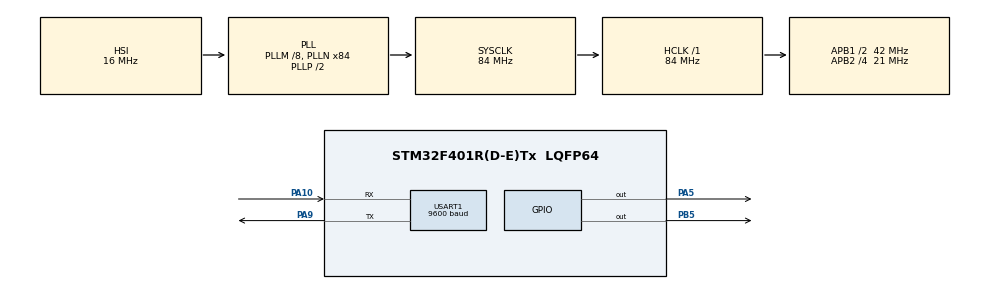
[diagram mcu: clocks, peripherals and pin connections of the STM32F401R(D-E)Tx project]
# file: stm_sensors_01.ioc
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Mcu.Family=STM32F4
Mcu.Name=STM32F401R(D-E)Tx
Mcu.Package=LQFP64
NVIC.PriorityGroup=NVIC_PRIORITYGROUP_4
NVIC.TIM1_BRK_TIM9_IRQn=true\:0\:0\:false\:false\:true\:true
NVIC.TIM1_UP_TIM10_IRQn=true\:0\:0\:false\:false\:true\:true
PA10.Mode=Asynchronous
PA10.Signal=USART1_RX
PA5.Signal=GPIO_Output
PA9.Mode=Asynchronous
PA9.Signal=USART1_TX
PB5.GPIO_ModeDefaultOutputPP=GPIO_MODE_OUTPUT_OD
PB5.GPIO_Speed=GPIO_SPEED_FREQ_VERY_HIGH
PB5.Signal=GPIO_Output
PH0\ -\ OSC_IN.Mode=HSE-External-Oscillator
PH0\ -\ OSC_IN.Signal=RCC_OSC_IN
PH1\ -\ OSC_OUT.Mode=HSE-External-Oscillator
PH1\ -\ OSC_OUT.Signal=RCC_OSC_OUT
ProjectManager.HeapSize=0x200
ProjectManager.StackSize=0x400
ProjectManager.TargetToolchain=SW4STM32
RCC.48MHZClocksFreq_Value=42000000
RCC.AHBFreq_Value=84000000
RCC.APB1CLKDivider=RCC_HCLK_DIV2
RCC.APB1Freq_Value=42000000
RCC.APB1TimFreq_Value=84000000
RCC.APB2CLKDivider=RCC_HCLK_DIV4
RCC.APB2Freq_Value=21000000
RCC.APB2TimFreq_Value=42000000
RCC.CortexFreq_Value=84000000
RCC.HCLKFreq_Value=84000000
RCC.HSE_VALUE=21000000
RCC.HSI_VALUE=16000000
RCC.LSE_VALUE=32768
RCC.PLLM=8
RCC.PLLN=84
RCC.SYSCLKFreq_VALUE=84000000
RCC.SYSCLKSource=RCC_SYSCLKSOURCE_PLLCLK
RCC.VCOOutputFreq_Value=168000000
TIM10.Period=49
TIM10.Prescaler=41999
TIM9.ClockDivision=TIM_CLOCKDIVISION_DIV1
TIM9.Period=999
TIM9.Prescaler=41999
USART1.BaudRate=9600
USART1.VirtualMode=VM_ASYNC
VP_TIM10_VS_ClockSourceINT.Mode=Enable_Timer
VP_TIM9_VS_ClockSourceINT.Mode=Internal
board=stm_sensors_01

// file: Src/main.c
/**
  ******************************************************************************
  * @file           : main.c
  * @brief          : Main program body
  ******************************************************************************
  ** This notice applies to any and all portions of this file
  * that are not between comment pairs USER CODE BEGIN and
  * USER CODE END. Other portions of this file, whether
  * inserted by the user or by software development tools
  * are owned by their respective copyright owners.
  *
  * COPYRIGHT(c) 2018 STMicroelectronics
  *
  * Redistribution and use in source and binary forms, with or without modification,
  * are permitted provided that the following conditions are met:
  *   1. Redistributions of source code must retain the above copyright notice,
  *      this list of conditions and the following disclaimer.
  *   2. Redistributions in binary form must reproduce the above copyright notice,
  *      this list of conditions and the following disclaimer in the documentation
  *      and/or other materials provided with the distribution.
  *   3. Neither the name of STMicroelectronics nor the names of its contributors
  *      may be used to endorse or promote products derived from this software
  *      without specific prior written permission.
  *
  * THIS SOFTWARE IS PROVIDED BY THE COPYRIGHT HOLDERS AND CONTRIBUTORS "AS IS"
  * AND ANY EXPRESS OR IMPLIED WARRANTIES, INCLUDING, BUT NOT LIMITED TO, THE
  * IMPLIED WARRANTIES OF MERCHANTABILITY AND FITNESS FOR A PARTICULAR PURPOSE ARE
  * DISCLAIMED. IN NO EVENT SHALL THE COPYRIGHT HOLDER OR CONTRIBUTORS BE LIABLE
  * FOR ANY DIRECT, INDIRECT, INCIDENTAL, SPECIAL, EXEMPLARY, OR CONSEQUENTIAL
  * DAMAGES (INCLUDING, BUT NOT LIMITED TO, PROCUREMENT OF SUBSTITUTE GOODS OR
  * SERVICES; LOSS OF USE, DATA, OR PROFITS; OR BUSINESS INTERRUPTION) HOWEVER
  * CAUSED AND ON ANY THEORY OF LIABILITY, WHETHER IN CONTRACT, STRICT LIABILITY,
  * OR TORT (INCLUDING NEGLIGENCE OR OTHERWISE) ARISING IN ANY WAY OUT OF THE USE
  * OF THIS SOFTWARE, EVEN IF ADVISED OF THE POSSIBILITY OF SUCH DAMAGE.
  *
  ******************************************************************************
  */
#include "main.h"
#include "stm32f4xx_hal.h"

/* USER CODE BEGIN Includes */
#include "main_usercode.h"
#include <stdio.h>
/* USER CODE END Includes */

TIM_HandleTypeDef htim9;
TIM_HandleTypeDef htim10;

UART_HandleTypeDef huart1;

/* USER CODE BEGIN PV */
/* Private variables ---------------------------------------------------------*/

/* USER CODE END PV */

void SystemClock_Config(void);
static void MX_GPIO_Init(void);
static void MX_USART1_UART_Init(void);
static void MX_TIM10_Init(void);
static void MX_TIM9_Init(void);

/* USER CODE BEGIN PFP */
/* Private function prototypes -----------------------------------------------*/

/* USER CODE END PFP */

/* USER CODE BEGIN 0 */
uint8_t GL_PROJECT_NAME[]="PROJECT OF STM SENSORS' EXPERIMENTS #2: TEMPERATURE SENSOR (DS18B20)\r\n";
/* USER CODE END 0 */

int main(void)
{

  /* MCU Configuration----------------------------------------------------------*/

  /* Reset of all peripherals, Initializes the Flash interface and the Systick. */
  HAL_Init();

  /* Configure the system clock */
  SystemClock_Config();

  /* Initialize all configured peripherals */
  MX_GPIO_Init();
  MX_USART1_UART_Init();
  MX_TIM10_Init();
  MX_TIM9_Init();

  /* Infinite loop */
  /* USER CODE BEGIN WHILE */
  while (1)
  {
    main_usercode();

  /* USER CODE END WHILE */

  }

}

void SystemClock_Config(void)
{

  RCC_OscInitTypeDef RCC_OscInitStruct;
  RCC_ClkInitTypeDef RCC_ClkInitStruct;

    /**Configure the main internal regulator output voltage
    */
  __HAL_RCC_PWR_CLK_ENABLE();

  __HAL_PWR_VOLTAGESCALING_CONFIG(PWR_REGULATOR_VOLTAGE_SCALE2);

    /**Initializes the CPU, AHB and APB busses clocks
    */
  RCC_OscInitStruct.OscillatorType = RCC_OSCILLATORTYPE_HSI;
  RCC_OscInitStruct.HSIState = RCC_HSI_ON;
  RCC_OscInitStruct.HSICalibrationValue = 16;
  RCC_OscInitStruct.PLL.PLLState = RCC_PLL_ON;
  RCC_OscInitStruct.PLL.PLLSource = RCC_PLLSOURCE_HSI;
  RCC_OscInitStruct.PLL.PLLM = 8;
  RCC_OscInitStruct.PLL.PLLN = 84;
  RCC_OscInitStruct.PLL.PLLP = RCC_PLLP_DIV2;
  RCC_OscInitStruct.PLL.PLLQ = 4;
  if (HAL_RCC_OscConfig(&RCC_OscInitStruct) != HAL_OK)
  {
    _Error_Handler(__FILE__, __LINE__);
  }

    /**Initializes the CPU, AHB and APB busses clocks
    */
  RCC_ClkInitStruct.ClockType = RCC_CLOCKTYPE_HCLK|RCC_CLOCKTYPE_SYSCLK
                              |RCC_CLOCKTYPE_PCLK1|RCC_CLOCKTYPE_PCLK2;
  RCC_ClkInitStruct.SYSCLKSource = RCC_SYSCLKSOURCE_PLLCLK;
  RCC_ClkInitStruct.AHBCLKDivider = RCC_SYSCLK_DIV1;
  RCC_ClkInitStruct.APB1CLKDivider = RCC_HCLK_DIV2;
  RCC_ClkInitStruct.APB2CLKDivider = RCC_HCLK_DIV4;

  if (HAL_RCC_ClockConfig(&RCC_ClkInitStruct, FLASH_LATENCY_2) != HAL_OK)
  {
    _Error_Handler(__FILE__, __LINE__);
  }

    /**Configure the Systick interrupt time
    */
  HAL_SYSTICK_Config(HAL_RCC_GetHCLKFreq()/1000);

    /**Configure the Systick
    */
  HAL_SYSTICK_CLKSourceConfig(SYSTICK_CLKSOURCE_HCLK);

  /* SysTick_IRQn interrupt configuration */
  HAL_NVIC_SetPriority(SysTick_IRQn, 0, 0);
}

/* TIM9 init function */
static void MX_TIM9_Init(void)
{

  TIM_ClockConfigTypeDef sClockSourceConfig;

  htim9.Instance = TIM9;
  htim9.Init.Prescaler = 41999;
  htim9.Init.CounterMode = TIM_COUNTERMODE_UP;
  htim9.Init.Period = 999;
  htim9.Init.ClockDivision = TIM_CLOCKDIVISION_DIV1;
  if (HAL_TIM_Base_Init(&htim9) != HAL_OK)
  {
    _Error_Handler(__FILE__, __LINE__);
  }

  sClockSourceConfig.ClockSource = TIM_CLOCKSOURCE_INTERNAL;
  if (HAL_TIM_ConfigClockSource(&htim9, &sClockSourceConfig) != HAL_OK)
  {
    _Error_Handler(__FILE__, __LINE__);
  }

}

/* TIM10 init function */
static void MX_TIM10_Init(void)
{

  htim10.Instance = TIM10;
  htim10.Init.Prescaler = 41999;
  htim10.Init.CounterMode = TIM_COUNTERMODE_UP;
  htim10.Init.Period = 49;
  htim10.Init.ClockDivision = TIM_CLOCKDIVISION_DIV1;
  if (HAL_TIM_Base_Init(&htim10) != HAL_OK)
  {
    _Error_Handler(__FILE__, __LINE__);
  }

}

/* USART1 init function */
static void MX_USART1_UART_Init(void)
{

  huart1.Instance = USART1;
  huart1.Init.BaudRate = 9600;
  huart1.Init.WordLength = UART_WORDLENGTH_8B;
  huart1.Init.StopBits = UART_STOPBITS_1;
  huart1.Init.Parity = UART_PARITY_NONE;
  huart1.Init.Mode = UART_MODE_TX_RX;
  huart1.Init.HwFlowCtl = UART_HWCONTROL_NONE;
  huart1.Init.OverSampling = UART_OVERSAMPLING_16;
  if (HAL_UART_Init(&huart1) != HAL_OK)
  {
    _Error_Handler(__FILE__, __LINE__);
  }

}

/** Configure pins as
        * Analog
        * Input
        * Output
        * EVENT_OUT
        * EXTI
*/
static void MX_GPIO_Init(void)
{

  GPIO_InitTypeDef GPIO_InitStruct;

  /* GPIO Ports Clock Enable */
  __HAL_RCC_GPIOH_CLK_ENABLE();
  __HAL_RCC_GPIOA_CLK_ENABLE();
  __HAL_RCC_GPIOB_CLK_ENABLE();

  /*Configure GPIO pin Output Level */
  HAL_GPIO_WritePin(GPIOA, GPIO_PIN_5, GPIO_PIN_RESET);

  /*Configure GPIO pin Output Level */
  HAL_GPIO_WritePin(GPIOB, GPIO_PIN_5, GPIO_PIN_RESET);

  /*Configure GPIO pin : PA5 */
  GPIO_InitStruct.Pin = GPIO_PIN_5;
  GPIO_InitStruct.Mode = GPIO_MODE_OUTPUT_PP;
  GPIO_InitStruct.Pull = GPIO_NOPULL;
  GPIO_InitStruct.Speed = GPIO_SPEED_FREQ_LOW;
  HAL_GPIO_Init(GPIOA, &GPIO_InitStruct);

  /*Configure GPIO pin : PB5 */
  GPIO_InitStruct.Pin = GPIO_PIN_5;
  GPIO_InitStruct.Mode = GPIO_MODE_OUTPUT_OD;
  GPIO_InitStruct.Pull = GPIO_NOPULL;
  GPIO_InitStruct.Speed = GPIO_SPEED_FREQ_VERY_HIGH;
  HAL_GPIO_Init(GPIOB, &GPIO_InitStruct);

}

void _Error_Handler(char *file, int line)
{
  while(1)
  {
  }
}

/************************ (C) COPYRIGHT STMicroelectronics *****END OF FILE****/
